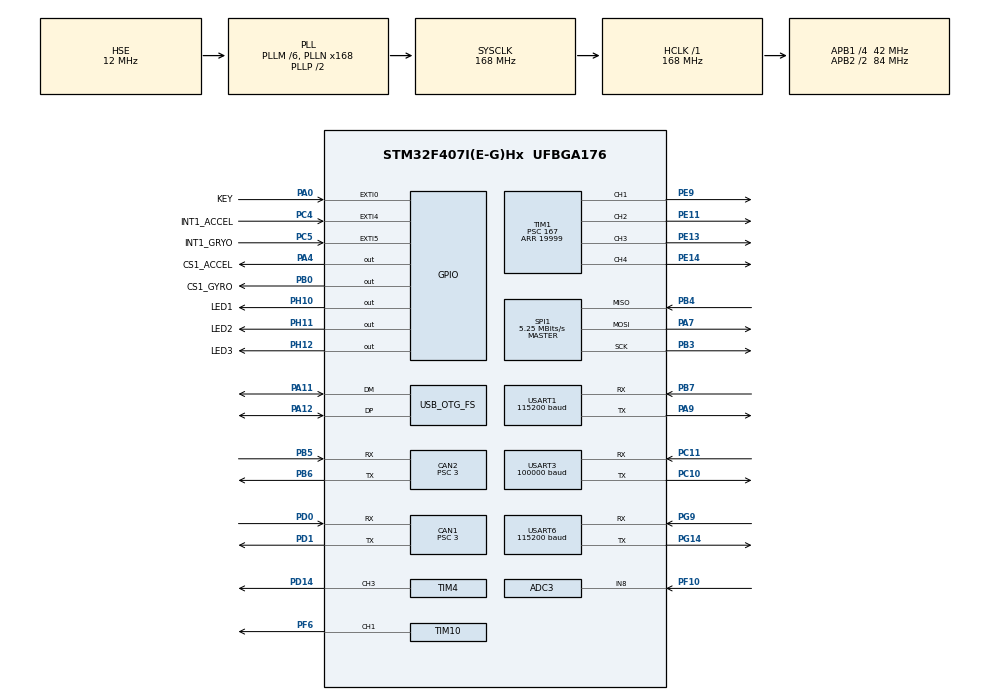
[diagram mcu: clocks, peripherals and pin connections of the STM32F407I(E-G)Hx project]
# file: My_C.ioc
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ADC1.Channel-0\#ChannelRegularConversion=ADC_CHANNEL_VREFINT
ADC1.ClockPrescaler=ADC_CLOCK_SYNC_PCLK_DIV4
ADC1.NbrOfConversionFlag=1
ADC1.Rank-0\#ChannelRegularConversion=1
ADC1.SamplingTime-0\#ChannelRegularConversion=ADC_SAMPLETIME_3CYCLES
ADC1.master=1
ADC3.Channel-0\#ChannelRegularConversion=ADC_CHANNEL_8
ADC3.ClockPrescaler=ADC_CLOCK_SYNC_PCLK_DIV4
ADC3.NbrOfConversionFlag=1
ADC3.Rank-0\#ChannelRegularConversion=1
ADC3.SamplingTime-0\#ChannelRegularConversion=ADC_SAMPLETIME_3CYCLES
CAN1.ABOM=ENABLE
CAN1.AWUM=ENABLE
CAN1.BS1=CAN_BS1_10TQ
CAN1.BS2=CAN_BS2_3TQ
CAN1.CalculateBaudRate=1000000
CAN1.CalculateTimeBit=1000
CAN1.CalculateTimeQuantum=71.42857142857143
CAN1.Prescaler=3
CAN1.TXFP=ENABLE
CAN2.ABOM=ENABLE
CAN2.AWUM=ENABLE
CAN2.BS1=CAN_BS1_10TQ
CAN2.BS2=CAN_BS2_3TQ
CAN2.CalculateBaudRate=1000000
CAN2.CalculateTimeBit=1000
CAN2.CalculateTimeQuantum=71.42857142857143
CAN2.Prescaler=3
CAN2.TXFP=ENABLE
Dma.Request0=SPI1_RX
Dma.Request1=SPI1_TX
Dma.Request2=USART3_RX
Dma.Request3=USART1_RX
Dma.Request4=USART1_TX
Dma.Request5=USART6_RX
Dma.Request6=USART6_TX
Dma.SPI1_RX.0.Direction=DMA_PERIPH_TO_MEMORY
Dma.SPI1_RX.0.FIFOMode=DMA_FIFOMODE_DISABLE
Dma.SPI1_RX.0.Instance=DMA2_Stream0
Dma.SPI1_RX.0.MemDataAlignment=DMA_MDATAALIGN_BYTE
Dma.SPI1_RX.0.MemInc=DMA_MINC_ENABLE
Dma.SPI1_RX.0.Mode=DMA_NORMAL
Dma.SPI1_RX.0.PeriphDataAlignment=DMA_PDATAALIGN_BYTE
Dma.SPI1_RX.0.PeriphInc=DMA_PINC_DISABLE
Dma.SPI1_RX.0.Priority=DMA_PRIORITY_VERY_HIGH
Dma.SPI1_TX.1.Direction=DMA_MEMORY_TO_PERIPH
Dma.SPI1_TX.1.FIFOMode=DMA_FIFOMODE_DISABLE
Dma.SPI1_TX.1.Instance=DMA2_Stream3
Dma.SPI1_TX.1.MemDataAlignment=DMA_MDATAALIGN_BYTE
Dma.SPI1_TX.1.MemInc=DMA_MINC_ENABLE
Dma.SPI1_TX.1.Mode=DMA_NORMAL
Dma.SPI1_TX.1.PeriphDataAlignment=DMA_PDATAALIGN_BYTE
Dma.SPI1_TX.1.PeriphInc=DMA_PINC_DISABLE
Dma.SPI1_TX.1.Priority=DMA_PRIORITY_HIGH
Dma.USART1_RX.3.Direction=DMA_PERIPH_TO_MEMORY
Dma.USART1_RX.3.FIFOMode=DMA_FIFOMODE_DISABLE
Dma.USART1_RX.3.Instance=DMA2_Stream2
Dma.USART1_RX.3.MemDataAlignment=DMA_MDATAALIGN_BYTE
Dma.USART1_RX.3.MemInc=DMA_MINC_ENABLE
Dma.USART1_RX.3.Mode=DMA_CIRCULAR
Dma.USART1_RX.3.PeriphDataAlignment=DMA_PDATAALIGN_BYTE
Dma.USART1_RX.3.PeriphInc=DMA_PINC_DISABLE
Dma.USART1_RX.3.Priority=DMA_PRIORITY_HIGH
Dma.USART1_TX.4.Direction=DMA_MEMORY_TO_PERIPH
Dma.USART1_TX.4.FIFOMode=DMA_FIFOMODE_DISABLE
Dma.USART1_TX.4.Instance=DMA2_Stream7
Dma.USART1_TX.4.MemDataAlignment=DMA_MDATAALIGN_BYTE
Dma.USART1_TX.4.MemInc=DMA_MINC_ENABLE
Dma.USART1_TX.4.Mode=DMA_NORMAL
Dma.USART1_TX.4.PeriphDataAlignment=DMA_PDATAALIGN_BYTE
Dma.USART1_TX.4.PeriphInc=DMA_PINC_DISABLE
Dma.USART1_TX.4.Priority=DMA_PRIORITY_HIGH
Dma.USART3_RX.2.Direction=DMA_PERIPH_TO_MEMORY
Dma.USART3_RX.2.FIFOMode=DMA_FIFOMODE_DISABLE
Dma.USART3_RX.2.Instance=DMA1_Stream1
Dma.USART3_RX.2.MemDataAlignment=DMA_MDATAALIGN_BYTE
Dma.USART3_RX.2.MemInc=DMA_MINC_ENABLE
Dma.USART3_RX.2.Mode=DMA_CIRCULAR
Dma.USART3_RX.2.PeriphDataAlignment=DMA_PDATAALIGN_BYTE
Dma.USART3_RX.2.PeriphInc=DMA_PINC_DISABLE
Dma.USART3_RX.2.Priority=DMA_PRIORITY_HIGH
Dma.USART6_RX.5.Direction=DMA_PERIPH_TO_MEMORY
Dma.USART6_RX.5.FIFOMode=DMA_FIFOMODE_DISABLE
Dma.USART6_RX.5.Instance=DMA2_Stream1
Dma.USART6_RX.5.MemDataAlignment=DMA_MDATAALIGN_BYTE
Dma.USART6_RX.5.MemInc=DMA_MINC_ENABLE
Dma.USART6_RX.5.Mode=DMA_CIRCULAR
Dma.USART6_RX.5.PeriphDataAlignment=DMA_PDATAALIGN_BYTE
Dma.USART6_RX.5.PeriphInc=DMA_PINC_DISABLE
Dma.USART6_RX.5.Priority=DMA_PRIORITY_HIGH
Dma.USART6_TX.6.Direction=DMA_MEMORY_TO_PERIPH
Dma.USART6_TX.6.FIFOMode=DMA_FIFOMODE_DISABLE
Dma.USART6_TX.6.Instance=DMA2_Stream6
Dma.USART6_TX.6.MemDataAlignment=DMA_MDATAALIGN_BYTE
Dma.USART6_TX.6.MemInc=DMA_MINC_ENABLE
Dma.USART6_TX.6.Mode=DMA_NORMAL
Dma.USART6_TX.6.PeriphDataAlignment=DMA_PDATAALIGN_BYTE
Dma.USART6_TX.6.PeriphInc=DMA_PINC_DISABLE
Dma.USART6_TX.6.Priority=DMA_PRIORITY_LOW
FREERTOS.Tasks01=MonitorTask,3,512,StartMonitorTask,As weak,NULL,Dynamic,NULL,NULL;CommunityTask,2,512,StartCommunityTask,As weak,NULL,Dynamic,NULL,NULL;ControlTask,3,1024,StartControlTask,As weak,NULL,Dynamic,NULL,NULL;LedTask,1,128,StartLedTask,As weak,NULL,Dynamic,NULL,NULL
Mcu.Family=STM32F4
Mcu.Name=STM32F407I(E-G)Hx
Mcu.Package=UFBGA176
NVIC.CAN1_RX0_IRQn=true\:5\:0\:false\:false\:true\:true\:true\:true\:true
NVIC.CAN2_RX0_IRQn=true\:5\:0\:false\:false\:true\:true\:true\:true\:true
NVIC.DMA1_Stream1_IRQn=true\:5\:0\:false\:false\:true\:true\:false\:true\:true
NVIC.DMA2_Stream0_IRQn=true\:5\:0\:false\:false\:true\:true\:false\:true\:true
NVIC.DMA2_Stream1_IRQn=true\:5\:0\:false\:false\:true\:true\:false\:true\:true
NVIC.DMA2_Stream2_IRQn=true\:5\:0\:false\:false\:true\:true\:false\:true\:true
NVIC.DMA2_Stream3_IRQn=true\:5\:0\:false\:false\:true\:true\:false\:true\:true
NVIC.DMA2_Stream6_IRQn=true\:5\:0\:false\:false\:true\:true\:false\:true\:true
NVIC.DMA2_Stream7_IRQn=true\:5\:0\:false\:false\:true\:true\:false\:true\:true
NVIC.EXTI0_IRQn=true\:5\:0\:false\:false\:true\:true\:true\:true\:true
NVIC.EXTI4_IRQn=true\:5\:0\:false\:false\:true\:true\:true\:true\:true
NVIC.EXTI9_5_IRQn=true\:5\:0\:false\:false\:true\:true\:true\:true\:true
NVIC.OTG_FS_IRQn=true\:5\:0\:false\:false\:true\:true\:false\:true\:true
NVIC.PriorityGroup=NVIC_PRIORITYGROUP_4
NVIC.TIM2_IRQn=true\:15\:0\:false\:false\:true\:false\:false\:true\:true
NVIC.TIM4_IRQn=true\:5\:0\:false\:false\:true\:true\:true\:true\:true
NVIC.TimeBase=TIM2_IRQn
NVIC.TimeBaseIP=TIM2
NVIC.USART1_IRQn=true\:5\:0\:false\:false\:true\:true\:true\:true\:true
NVIC.USART3_IRQn=true\:5\:0\:false\:false\:true\:true\:true\:true\:true
NVIC.USART6_IRQn=true\:5\:0\:false\:false\:true\:true\:true\:true\:true
PA0-WKUP.GPIO_Label=KEY
PA0-WKUP.GPIO_ModeDefaultEXTI=GPIO_MODE_IT_FALLING
PA0-WKUP.GPIO_PuPd=GPIO_PULLUP
PA0-WKUP.Signal=GPXTI0
PA11.Mode=Device_Only
PA11.Signal=USB_OTG_FS_DM
PA12.Mode=Device_Only
PA12.Signal=USB_OTG_FS_DP
PA13.Mode=Serial_Wire
PA13.Signal=SYS_JTMS-SWDIO
PA14.Mode=Serial_Wire
PA14.Signal=SYS_JTCK-SWCLK
PA4.GPIO_Label=CS1_ACCEL
PA4.GPIO_PuPd=GPIO_PULLUP
PA4.GPIO_Speed=GPIO_SPEED_FREQ_HIGH
PA4.PinState=GPIO_PIN_SET
PA4.Signal=GPIO_Output
PA7.Mode=Full_Duplex_Master
PA7.Signal=SPI1_MOSI
PA9.Mode=Asynchronous
PA9.Signal=USART1_TX
PB0.GPIO_Label=CS1_GYRO
PB0.GPIO_PuPd=GPIO_PULLUP
PB0.GPIO_Speed=GPIO_SPEED_FREQ_HIGH
PB0.PinState=GPIO_PIN_SET
PB0.Signal=GPIO_Output
PB3.Mode=Full_Duplex_Master
PB3.Signal=SPI1_SCK
PB4.Mode=Full_Duplex_Master
PB4.Signal=SPI1_MISO
PB5.Mode=CAN_Activate
PB5.Signal=CAN2_RX
PB6.Mode=CAN_Activate
PB6.Signal=CAN2_TX
PB7.Mode=Asynchronous
PB7.Signal=USART1_RX
PC10.Mode=Asynchronous
PC10.Signal=USART3_TX
PC11.Mode=Asynchronous
PC11.Signal=USART3_RX
PC4.GPIO_Label=INT1_ACCEL
PC4.GPIO_ModeDefaultEXTI=GPIO_MODE_IT_FALLING
PC4.GPIO_PuPd=GPIO_PULLUP
PC4.Signal=GPXTI4
PC5.GPIO_Label=INT1_GRYO
PC5.GPIO_ModeDefaultEXTI=GPIO_MODE_IT_FALLING
PC5.GPIO_PuPd=GPIO_PULLUP
PC5.Signal=GPXTI5
PD0.Mode=CAN_Activate
PD0.Signal=CAN1_RX
PD1.Mode=CAN_Activate
PD1.Signal=CAN1_TX
PD14.Signal=S_TIM4_CH3
PE11.Signal=S_TIM1_CH2
PE13.Signal=S_TIM1_CH3
PE14.Signal=S_TIM1_CH4
PE9.Signal=S_TIM1_CH1
PF10.Mode=IN8
PF10.Signal=ADC3_IN8
PF6.GPIO_PuPd=GPIO_PULLUP
PF6.GPIO_Speed=GPIO_SPEED_FREQ_HIGH
PF6.Signal=S_TIM10_CH1
PG14.Mode=Asynchronous
PG14.Signal=USART6_TX
PG9.Mode=Asynchronous
PG9.Signal=USART6_RX
PH0-OSC_IN.Mode=HSE-External-Oscillator
PH0-OSC_IN.Signal=RCC_OSC_IN
PH1-OSC_OUT.Mode=HSE-External-Oscillator
PH1-OSC_OUT.Signal=RCC_OSC_OUT
PH10.GPIO_Label=LED1
PH10.Signal=GPIO_Output
PH11.GPIO_Label=LED2
PH11.Signal=GPIO_Output
PH12.GPIO_Label=LED3
PH12.Signal=GPIO_Output
ProjectManager.HeapSize=0x200
ProjectManager.StackSize=0x400
ProjectManager.TargetToolchain=MDK-ARM V5.32
RCC.48MHZClocksFreq_Value=48000000
RCC.AHBFreq_Value=168000000
RCC.APB1CLKDivider=RCC_HCLK_DIV4
RCC.APB1Freq_Value=42000000
RCC.APB1TimFreq_Value=84000000
RCC.APB2CLKDivider=RCC_HCLK_DIV2
RCC.APB2Freq_Value=84000000
RCC.APB2TimFreq_Value=168000000
RCC.CortexFreq_Value=168000000
RCC.HCLKFreq_Value=168000000
RCC.HSE_VALUE=12000000
RCC.HSI_VALUE=16000000
RCC.LSE_VALUE=32768
RCC.PLLM=6
RCC.PLLN=168
RCC.PLLQ=7
RCC.SYSCLKFreq_VALUE=168000000
RCC.SYSCLKSource=RCC_SYSCLKSOURCE_PLLCLK
RCC.VCOOutputFreq_Value=336000000
SH.S_TIM10_CH1.0=TIM10_CH1,PWM Generation1 CH1
SH.S_TIM1_CH1.0=TIM1_CH1,PWM Generation1 CH1
SH.S_TIM1_CH2.0=TIM1_CH2,PWM Generation2 CH2
SH.S_TIM1_CH3.0=TIM1_CH3,PWM Generation3 CH3
SH.S_TIM1_CH4.0=TIM1_CH4,PWM Generation4 CH4
SH.S_TIM4_CH3.0=TIM4_CH3,PWM Generation3 CH3
SPI1.BaudRatePrescaler=SPI_BAUDRATEPRESCALER_16
SPI1.CLKPhase=SPI_PHASE_2EDGE
SPI1.CLKPolarity=SPI_POLARITY_HIGH
SPI1.CalculateBaudRate=5.25 MBits/s
SPI1.Direction=SPI_DIRECTION_2LINES
SPI1.Mode=SPI_MODE_MASTER
SPI1.VirtualType=VM_MASTER
TIM1.Channel-PWM\ Generation1\ CH1=TIM_CHANNEL_1
TIM1.Channel-PWM\ Generation2\ CH2=TIM_CHANNEL_2
TIM1.Channel-PWM\ Generation3\ CH3=TIM_CHANNEL_3
TIM1.Channel-PWM\ Generation4\ CH4=TIM_CHANNEL_4
TIM1.Period=19999
TIM1.Prescaler=167
TIM10.Channel=TIM_CHANNEL_1
TIM10.Period=4999
TIM4.AutoReloadPreload=TIM_AUTORELOAD_PRELOAD_ENABLE
TIM4.Channel-PWM\ Generation3\ CH3=TIM_CHANNEL_3
TIM4.Period=499
TIM4.Prescaler=83
USART1.BaudRate=115200
USART1.VirtualMode=VM_ASYNC
USART3.BaudRate=100000
USART3.Parity=PARITY_EVEN
USART3.VirtualMode=VM_ASYNC
USART6.BaudRate=115200
USART6.VirtualMode=VM_ASYNC
USB_DEVICE.APP_RX_DATA_SIZE-CDC_FS=128
USB_DEVICE.APP_TX_DATA_SIZE-CDC_FS=128
USB_DEVICE.CLASS_NAME_FS=CDC
USB_DEVICE.VirtualMode-CDC_FS=Cdc
USB_DEVICE.VirtualModeFS=Cdc_FS
USB_OTG_FS.VirtualMode=Device_Only
VP_ADC1_TempSens_Input.Mode=IN-TempSens
VP_ADC1_Vref_Input.Mode=IN-Vrefint
VP_FREERTOS_VS_CMSIS_V1.Mode=CMSIS_V1
VP_IWDG_VS_IWDG.Mode=IWDG_Activate
VP_SYS_VS_tim2.Mode=TIM2
VP_TIM10_VS_ClockSourceINT.Mode=Enable_Timer
VP_TIM4_VS_ClockSourceINT.Mode=Internal
VP_USB_DEVICE_VS_USB_DEVICE_CDC_FS.Mode=CDC_FS
board=custom

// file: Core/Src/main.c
/* USER CODE BEGIN Header */
/**
  ******************************************************************************
  * @file           : main.c
  * @brief          : Main program body
  ******************************************************************************
  * @attention
  *
  * Copyright (c) 2024 STMicroelectronics.
  * All rights reserved.
  *
  * This software is licensed under terms that can be found in the LICENSE file
  * in the root directory of this software component.
  * If no LICENSE file comes with this software, it is provided AS-IS.
  *
  ******************************************************************************
  */
/* USER CODE END Header */
#include "main.h"
#include "cmsis_os.h"
#include "adc.h"
#include "can.h"
#include "dma.h"
#include "spi.h"
#include "tim.h"
#include "usart.h"
#include "usb_device.h"
#include "gpio.h"

/* USER CODE BEGIN Includes */
#include "iwdg.h"
#include "driver.h"
#include "device.h"
#include "dart_app.h"
/* USER CODE END Includes */

void SystemClock_Config(void);
void MX_FREERTOS_Init(void);

int main(void)
{

  /* MCU Configuration--------------------------------------------------------*/

  /* Reset of all peripherals, Initializes the Flash interface and the Systick. */
  HAL_Init();

  /* Configure the system clock */
  SystemClock_Config();

  /* Initialize all configured peripherals */
  MX_GPIO_Init();
  MX_DMA_Init();
  MX_SPI1_Init();
  MX_TIM10_Init();
  MX_CAN1_Init();
  MX_CAN2_Init();
  MX_USART3_UART_Init();
  MX_USART1_UART_Init();
  MX_USART6_UART_Init();
  MX_TIM4_Init();
  MX_ADC1_Init();
  MX_ADC3_Init();
  MX_TIM1_Init();
  /* USER CODE BEGIN 2 */
  /* Init order: motor objects before CAN RX IRQ, then drivers, devices, app */
#if DART_IWDG_ENABLE
  MX_IWDG_Init();
#endif
  MX_USB_DEVICE_Init();
  Dart_Motor_Init();
  DRIVER_Init();
  DEVICE_Init();
  Dart_App_Init();
  /* USER CODE END 2 */

  /* Call init function for freertos objects (in cmsis_os2.c) */
  MX_FREERTOS_Init();

  /* Start scheduler */
  osKernelStart();

  /* We should never get here as control is now taken by the scheduler */

  /* Infinite loop */
  while (1)
  {

  }
}

void SystemClock_Config(void)
{
  RCC_OscInitTypeDef RCC_OscInitStruct = {0};
  RCC_ClkInitTypeDef RCC_ClkInitStruct = {0};

  /** Configure the main internal regulator output voltage
  */
  __HAL_RCC_PWR_CLK_ENABLE();
  __HAL_PWR_VOLTAGESCALING_CONFIG(PWR_REGULATOR_VOLTAGE_SCALE1);

  /** Initializes the RCC Oscillators according to the specified parameters
  * in the RCC_OscInitTypeDef structure.
  */
  RCC_OscInitStruct.OscillatorType = RCC_OSCILLATORTYPE_LSI|RCC_OSCILLATORTYPE_HSE;
  RCC_OscInitStruct.HSEState = RCC_HSE_ON;
  RCC_OscInitStruct.LSIState = RCC_LSI_ON;
  RCC_OscInitStruct.PLL.PLLState = RCC_PLL_ON;
  RCC_OscInitStruct.PLL.PLLSource = RCC_PLLSOURCE_HSE;
  RCC_OscInitStruct.PLL.PLLM = 6;
  RCC_OscInitStruct.PLL.PLLN = 168;
  RCC_OscInitStruct.PLL.PLLP = RCC_PLLP_DIV2;
  RCC_OscInitStruct.PLL.PLLQ = 7;
  if (HAL_RCC_OscConfig(&RCC_OscInitStruct) != HAL_OK)
  {
    Error_Handler();
  }

  /** Initializes the CPU, AHB and APB buses clocks
  */
  RCC_ClkInitStruct.ClockType = RCC_CLOCKTYPE_HCLK|RCC_CLOCKTYPE_SYSCLK
                              |RCC_CLOCKTYPE_PCLK1|RCC_CLOCKTYPE_PCLK2;
  RCC_ClkInitStruct.SYSCLKSource = RCC_SYSCLKSOURCE_PLLCLK;
  RCC_ClkInitStruct.AHBCLKDivider = RCC_SYSCLK_DIV1;
  RCC_ClkInitStruct.APB1CLKDivider = RCC_HCLK_DIV4;
  RCC_ClkInitStruct.APB2CLKDivider = RCC_HCLK_DIV2;

  if (HAL_RCC_ClockConfig(&RCC_ClkInitStruct, FLASH_LATENCY_5) != HAL_OK)
  {
    Error_Handler();
  }
}

void HAL_TIM_PeriodElapsedCallback(TIM_HandleTypeDef *htim)
{
  if (htim->Instance == TIM2)
  {
    HAL_IncTick();
  }
}

void Error_Handler(void)
{
  __disable_irq();
  while (1)
  {
  }
}
